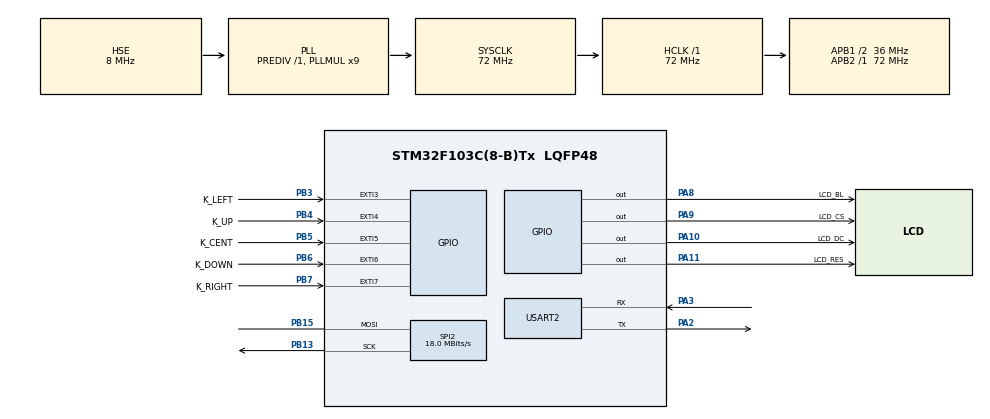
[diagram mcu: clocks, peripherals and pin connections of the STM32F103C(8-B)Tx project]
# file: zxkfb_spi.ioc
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Dma.Request0=SPI2_RX
Dma.Request1=SPI2_TX
Dma.SPI2_RX.0.Direction=DMA_PERIPH_TO_MEMORY
Dma.SPI2_RX.0.Instance=DMA1_Channel4
Dma.SPI2_RX.0.MemDataAlignment=DMA_MDATAALIGN_BYTE
Dma.SPI2_RX.0.MemInc=DMA_MINC_ENABLE
Dma.SPI2_RX.0.Mode=DMA_NORMAL
Dma.SPI2_RX.0.PeriphDataAlignment=DMA_PDATAALIGN_BYTE
Dma.SPI2_RX.0.PeriphInc=DMA_PINC_DISABLE
Dma.SPI2_RX.0.Priority=DMA_PRIORITY_HIGH
Dma.SPI2_TX.1.Direction=DMA_MEMORY_TO_PERIPH
Dma.SPI2_TX.1.Instance=DMA1_Channel5
Dma.SPI2_TX.1.MemDataAlignment=DMA_MDATAALIGN_BYTE
Dma.SPI2_TX.1.MemInc=DMA_MINC_ENABLE
Dma.SPI2_TX.1.Mode=DMA_NORMAL
Dma.SPI2_TX.1.PeriphDataAlignment=DMA_PDATAALIGN_BYTE
Dma.SPI2_TX.1.PeriphInc=DMA_PINC_DISABLE
Dma.SPI2_TX.1.Priority=DMA_PRIORITY_HIGH
Mcu.Family=STM32F1
Mcu.Name=STM32F103C(8-B)Tx
Mcu.Package=LQFP48
NVIC.DMA1_Channel4_IRQn=true\:0\:0\:false\:false\:true\:false\:true\:true
NVIC.DMA1_Channel5_IRQn=true\:0\:0\:false\:false\:true\:false\:true\:true
NVIC.PriorityGroup=NVIC_PRIORITYGROUP_4
PA10.GPIO_Label=LCD_DC
PA10.GPIO_Speed=GPIO_SPEED_FREQ_HIGH
PA10.Signal=GPIO_Output
PA11.GPIO_Label=LCD_RES
PA11.GPIO_Speed=GPIO_SPEED_FREQ_HIGH
PA11.Signal=GPIO_Output
PA2.Mode=Asynchronous
PA2.Signal=USART2_TX
PA3.Mode=Asynchronous
PA3.Signal=USART2_RX
PA8.GPIO_Label=LCD_BL
PA8.GPIO_Speed=GPIO_SPEED_FREQ_HIGH
PA8.PinState=GPIO_PIN_RESET
PA8.Signal=GPIO_Output
PA9.GPIO_Label=LCD_CS
PA9.GPIO_Speed=GPIO_SPEED_FREQ_HIGH
PA9.Signal=GPIO_Output
PB13.Mode=Simplex_Bidirectional_Master
PB13.Signal=SPI2_SCK
PB15.Mode=Simplex_Bidirectional_Master
PB15.Signal=SPI2_MOSI
PB3.GPIO_Label=K_LEFT
PB3.GPIO_ModeDefaultEXTI=GPIO_MODE_IT_FALLING
PB3.Signal=GPXTI3
PB4.GPIO_Label=K_UP
PB4.GPIO_ModeDefaultEXTI=GPIO_MODE_IT_FALLING
PB4.Signal=GPXTI4
PB5.GPIO_Label=K_CENT
PB5.GPIO_ModeDefaultEXTI=GPIO_MODE_IT_FALLING
PB5.Signal=GPXTI5
PB6.GPIO_Label=K_DOWN
PB6.GPIO_ModeDefaultEXTI=GPIO_MODE_IT_FALLING
PB6.Signal=GPXTI6
PB7.GPIO_Label=K_RIGHT
PB7.GPIO_ModeDefaultEXTI=GPIO_MODE_IT_FALLING
PB7.Signal=GPXTI7
PD0-OSC_IN.Mode=HSE-External-Oscillator
PD0-OSC_IN.Signal=RCC_OSC_IN
PD1-OSC_OUT.Mode=HSE-External-Oscillator
PD1-OSC_OUT.Signal=RCC_OSC_OUT
ProjectManager.HeapSize=0x200
ProjectManager.StackSize=0x400
ProjectManager.TargetToolchain=MDK-ARM V5
RCC.AHBFreq_Value=72000000
RCC.APB1CLKDivider=RCC_HCLK_DIV2
RCC.APB1Freq_Value=36000000
RCC.APB1TimFreq_Value=72000000
RCC.APB2Freq_Value=72000000
RCC.APB2TimFreq_Value=72000000
RCC.HCLKFreq_Value=72000000
RCC.PLLMUL=RCC_PLL_MUL9
RCC.PLLSourceVirtual=RCC_PLLSOURCE_HSE
RCC.SYSCLKFreq_VALUE=72000000
RCC.SYSCLKSource=RCC_SYSCLKSOURCE_PLLCLK
RCC.USBFreq_Value=72000000
SPI2.BaudRatePrescaler=SPI_BAUDRATEPRESCALER_2
SPI2.CalculateBaudRate=18.0 MBits/s
SPI2.Direction=SPI_DIRECTION_1LINE
SPI2.Mode=SPI_MODE_MASTER
SPI2.VirtualType=VM_MASTER
USART2.VirtualMode=VM_ASYNC
VP_SYS_VS_ND.Mode=No_Debug
board=custom

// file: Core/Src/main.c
/* USER CODE BEGIN Header */
/**
  ******************************************************************************
  * @file           : main.c
  * @brief          : Main program body
  ******************************************************************************
  * @attention
  *
  * Copyright (c) 2023 STMicroelectronics.
  * All rights reserved.
  *
  * This software is licensed under terms that can be found in the LICENSE file
  * in the root directory of this software component.
  * If no LICENSE file comes with this software, it is provided AS-IS.
  *
  ******************************************************************************
  */
/* USER CODE END Header */
#include "main.h"
#include "dma.h"
#include "spi.h"
#include "usart.h"
#include "gpio.h"

/* USER CODE BEGIN Includes */
#include "stdio.h"
#include "lcd_drv.h"
/* USER CODE END Includes */

/* USER CODE BEGIN PV */
extern const unsigned char gImage_img[];
/* USER CODE END PV */

void SystemClock_Config(void);

int main(void)
{

  /* MCU Configuration--------------------------------------------------------*/

  /* Reset of all peripherals, Initializes the Flash interface and the Systick. */
  HAL_Init();

  /* Configure the system clock */
  SystemClock_Config();

  /* Initialize all configured peripherals */
  MX_GPIO_Init();
  MX_DMA_Init();
  MX_SPI2_Init();
  MX_USART2_UART_Init();
  /* USER CODE BEGIN 2 */

	mylcd_init();

	//uint8_t rgb[]={0xf8, 0x00};//blue
	//uint8_t rgb[]={0x00, 0x1f};//red
	//uint8_t rgb[]={0x07, 0xE0};//green
	mylcd_startop();
	ST7735_FillRect(&st7735, 0, 0, 30, 50, ST7735_CYAN);
	//ST7735_FillRGBRect(&st7735, 30, 30, rgb, 30, 30);
	//ST7735_DrawBitmap(&st7735, 0, 0, (uint8_t*)gImage_img
	ST7735_DrawHLine(&st7735, 0, 0, 20, ST7735_RED);
	mylcd_stopop();

  /* USER CODE END 2 */

  /* Infinite loop */
  while (1)
  {

  }
}

void SystemClock_Config(void)
{
  RCC_OscInitTypeDef RCC_OscInitStruct = {0};
  RCC_ClkInitTypeDef RCC_ClkInitStruct = {0};

  /** Initializes the RCC Oscillators according to the specified parameters
  * in the RCC_OscInitTypeDef structure.
  */
  RCC_OscInitStruct.OscillatorType = RCC_OSCILLATORTYPE_HSE;
  RCC_OscInitStruct.HSEState = RCC_HSE_ON;
  RCC_OscInitStruct.HSEPredivValue = RCC_HSE_PREDIV_DIV1;
  RCC_OscInitStruct.HSIState = RCC_HSI_ON;
  RCC_OscInitStruct.PLL.PLLState = RCC_PLL_ON;
  RCC_OscInitStruct.PLL.PLLSource = RCC_PLLSOURCE_HSE;
  RCC_OscInitStruct.PLL.PLLMUL = RCC_PLL_MUL9;
  if (HAL_RCC_OscConfig(&RCC_OscInitStruct) != HAL_OK)
  {
    Error_Handler();
  }

  /** Initializes the CPU, AHB and APB buses clocks
  */
  RCC_ClkInitStruct.ClockType = RCC_CLOCKTYPE_HCLK|RCC_CLOCKTYPE_SYSCLK
                              |RCC_CLOCKTYPE_PCLK1|RCC_CLOCKTYPE_PCLK2;
  RCC_ClkInitStruct.SYSCLKSource = RCC_SYSCLKSOURCE_PLLCLK;
  RCC_ClkInitStruct.AHBCLKDivider = RCC_SYSCLK_DIV1;
  RCC_ClkInitStruct.APB1CLKDivider = RCC_HCLK_DIV2;
  RCC_ClkInitStruct.APB2CLKDivider = RCC_HCLK_DIV1;

  if (HAL_RCC_ClockConfig(&RCC_ClkInitStruct, FLASH_LATENCY_2) != HAL_OK)
  {
    Error_Handler();
  }
}

void Error_Handler(void)
{
  __disable_irq();
  while (1)
  {
  }
}
